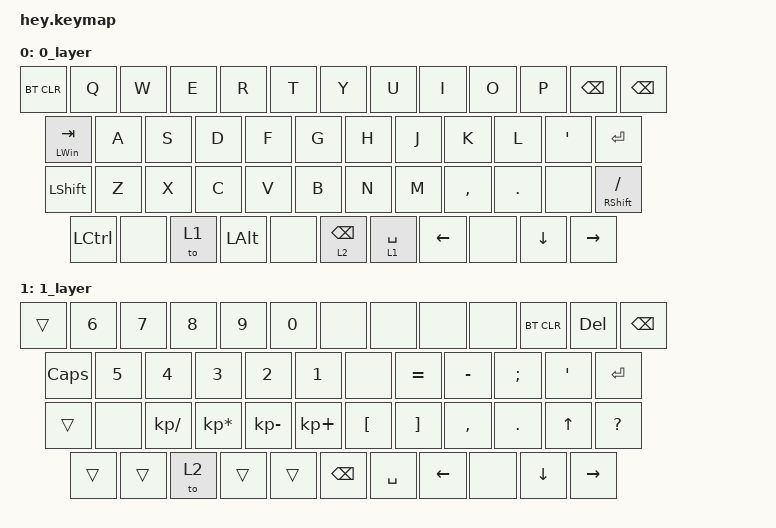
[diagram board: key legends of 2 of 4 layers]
/*
 * Copyright (c) 2020 The ZMK Contributors
 *
 * SPDX-License-Identifier: MIT
 */

#include <behaviors.dtsi>
#include <dt-bindings/zmk/keys.h>
#include <dt-bindings/zmk/bt.h>
#include <dt-bindings/zmk/outputs.h>


/ {
        keymap {
                compatible = "zmk,keymap";

                  0_layer {
// -----------------------------------------------------------------------------------------
// | ESC |  Q  |  W  |  E  |  R  |  T  |        |  Y  |  U   |  I  |  O  |  P  | BKSP ||
// | TAB  |  A  |  S  |  D  |  F  |  G  |         |  H  |  J   |  K  |  L  | ' |  ENTER   |
// | SHFT    |  Z  |  X  |  C  |  V  |  B  |        |  N  |  M   |  ,  |  .  ||  MT(mod_RSFT,KC_SLSH)   |
// | CTL || to(1) | ALT |  | LT(RAISE,BSPC) |      | LT(lower,SPC) |   left|| down | right |
                        bindings = <
   &bt BT_CLR  &kp Q &kp W &kp E &kp R &kp T                   &kp Y &kp U  &kp I  &kp O  &kp P   &kp BSPC &kp BSPC
   &mt LWIN TAB  &kp A  &kp S &kp D &kp F &kp G                   &kp H &kp J  &kp K  &kp L  &kp SQT   &kp ENTER
   &kp LSHFT &kp Z &kp X &kp C &kp V &kp B                  &kp N &kp M  &kp COMMA &kp DOT &none &mt RSHIFT SLASH
   &kp LCTL &none &to 1 &kp LALT &none &lt 2 BACKSPACE   &lt 1 SPACE &kp LEFT &none &kp DOWN &kp RIGHT
                        >;
                };

                1_layer {
// -----------------------------------------------------------------------------------------
// |     |  6  |  7  |  8  |  9 |  0    |     |         |     |     |     |    | &bt BT_CLR |   bksp  | |
// |  caps |  5  |  4  |  3  |  2 |  1  |     |         |     |  =  |  -  |  ;  |  '   |  ENTER   |
// |      | |   /  |   *  |   -  |  +   |  \  |         |   [ |  ]  |  ,  |  .   | up |   ? |
// |     ||  to(2)   | |  |      bspc         |         |     space      | left  | down | right |
                        bindings = <
   &trans &kp N6 &kp N7  &kp N8 &kp N9 &kp N0                              &none &none &none &none  &bt BT_CLR &kp DEL &kp BSPC
   &kp CAPS &kp N5  &kp N4  &kp N3  &kp N2  &kp N1                         &none &kp EQUAL &kp MINUS &kp SEMI &kp SQT &kp ENTER
   &trans &none  &kp KP_DIVIDE  &kp KP_MULTIPLY &kp KP_MINUS &kp KP_PLUS   &kp LBKT  &kp RBKT &kp COMMA &kp DOT &kp UP &kp QMARK
   &trans &trans &to 2 &trans  &trans         &kp BSPC               &kp SPACE         &kp LEFT &none &kp DOWN &kp RIGHT
                        >;
                };

                2_layer {
// -----------------------------------------------------------------------------------------
// |    | F1  |  F2 |  F3 |  F4 |  F5 |            |  F6  |  F7 |  F8 |  F9 | F10 |     | |
// |     | home | end | pgup | pgdown ||           |     |      |     |  F11| F12 |         |
// |      | print | ins | scroll | pause | |       |           |     |     |     | up  |    |
// |     |  to(3) |     |                  |       |                   | left | down | right |
                        bindings = <
   &trans  &kp F1 &kp F2 &kp F3 &kp F4  &kp F5               &kp F6  &kp F7 &kp F8 &kp F9 &kp F10 &trans &trans
   &trans &kp HOME &kp END &kp PG_UP &kp PG_DN &none       &none &none &none &kp F11 &kp F12           &trans
   &trans  &kp PSCRN  &kp INS &kp SLCK &kp PAUSE_BREAK &none    &none   &none   &none   &kp UP &none   &trans
   &trans &trans &to 3  &trans            &trans             &trans     &kp LEFT  &trans   &kp DOWN  &kp RIGHT
                        >;
                };

                3_layer {
// -----------------------------------------------------------------------------------------
// | ~  |  !  |  @  |  #  |  $  |  %  |         |  ^  |  &  |  *  |  (  |  )  |      ||
// |      |    |    |    |    |   |             |   |  +  |  _  |  :  | "    |       |
// |      |    |     |    |     |    |          | { | } | | | \   |        |          |
// |       | to(0)   |    |      |              |                |     |      |      |
                        bindings = <
   &kp TILD &kp EXCL &kp AT &kp HASH &kp DLLR &kp PRCNT     &kp CARET  &kp AMPS &kp STAR &kp LPAR &kp RPAR &kp DEL &kp DEL
   &trans   &none   &none   &none   &none   &none           &none   &kp KP_PLUS &kp UNDER  &kp COLON   &kp DQT       &trans
   &trans   &reset   &none        &none       &none         &kp LBRC  &kp RBRC   &kp PIPE  &kp NON_US_BSLH   &none  &trans
   &trans   &trans &to 0   &trans          &trans           &trans      &trans     &trans        &trans    &trans
                        >;
                };

        };
};
